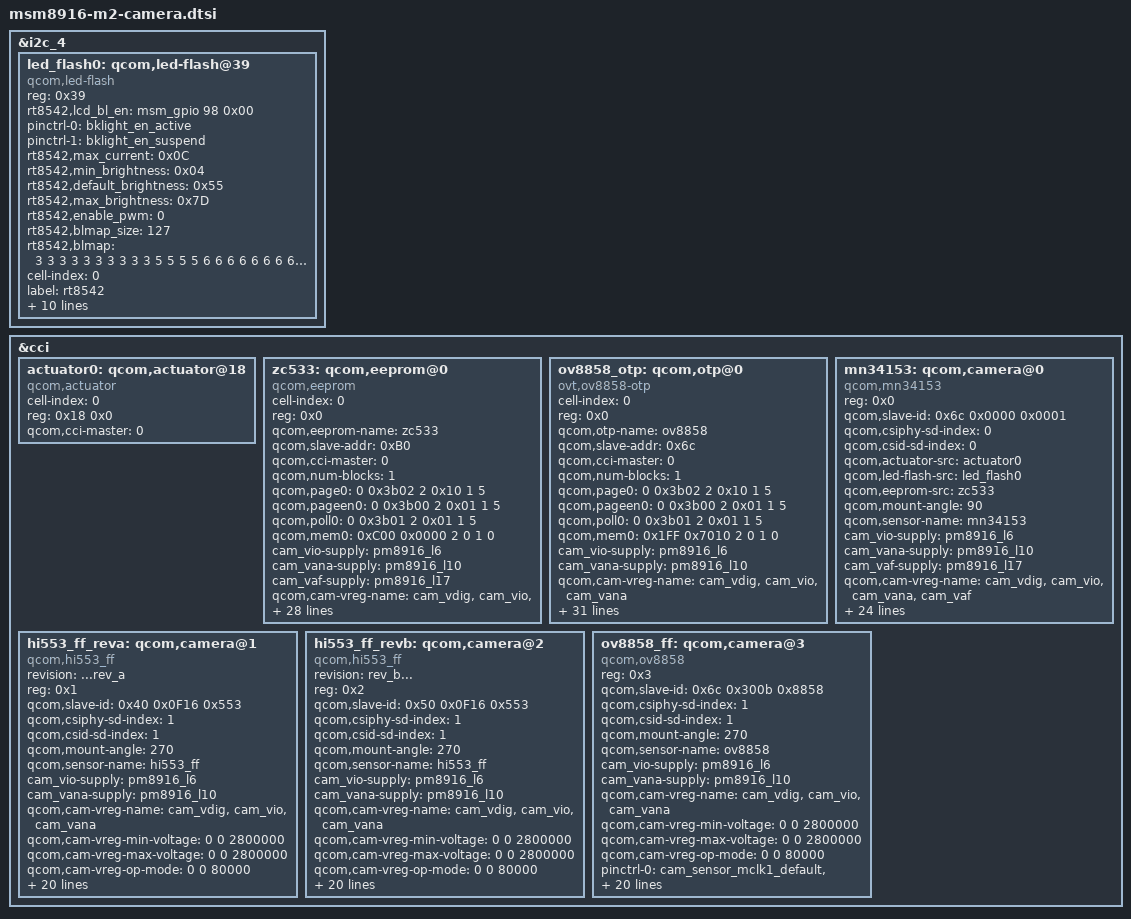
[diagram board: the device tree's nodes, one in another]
/*
 * Copyright (c) 2013, The Linux Foundation. All rights reserved.
 *
 * This program is free software; you can redistribute it and/or modify
 * it under the terms of the GNU General Public License version 2 and
 * only version 2 as published by the Free Software Foundation.
 *
 * This program is distributed in the hope that it will be useful,
 * but WITHOUT ANY WARRANTY; without even the implied warranty of
 * MERCHANTABILITY or FITNESS FOR A PARTICULAR PURPOSE.  See the
 * GNU General Public License for more details.
 */

&i2c_4 {
	led_flash0: qcom,led-flash@39 {
		status = "ok";
		compatible = "qcom,led-flash";
		reg = <0x39>;
		rt8542,lcd_bl_en = <&msm_gpio 98 0x00>;
		pinctrl-names = "default", "sleep";
		pinctrl-0 = <&bklight_en_active>;
		pinctrl-1 = <&bklight_en_suspend>;
		rt8542,max_current = <0x0C>;
		rt8542,min_brightness = <0x04>;
		//rt8542,default_brightness = <0x66>;  //77(0x4D)
		rt8542,default_brightness = <0x55>;	//46(0x2E)
		rt8542,max_brightness = <0x7D>;
		rt8542,enable_pwm = <0>;
		rt8542,blmap_size = <127>;
		rt8542,blmap = <
			3 3 3 3 3 3 3 3 3 3             //9
				5 5 5 5 6 6 6 6 6 6 				//19
				6 6 6 7 7 7 7 7 7 7 				//29
				7 10 10 11 11 11 12 12 12 12 	//39
				14 14 14 14 14 14 15 17 17 17 	//49
				17 19 19 19 21 22 23 23 23 25 	//59
				26 26 29 30 31 32 33 35 35 36	//69
				37 37 38 38 38 39 39 43 43 44 	//79
				44 44 45 45 46 46 46 47 49 50 	//89
				52 52 55 57 59 63 66 68 71 72   //99
				74 74 74 77 78 79 79 81 84 85	//109
				86 88 89 89 89 91 96 99 105 109	//119
				112 115 116 119 122 125 126>;

		cell-index = <0>;
		label                   = "rt8542";
		qcom,flash-name         = "rt8542";
		qcom,slave-id           = <0x39 0x00 0x0011>;
		qcom,flash-type         = <1>;              // LED_FLASH
		qcom,gpio-no-mux        = <0>;
		gpios                   = <&msm_gpio 31 0>; // FLASH_STROBE_TRIG, GPIO 31
		qcom,gpio-flash-en      = <0>;
		qcom,gpio-req-tbl-num   = <0>;
		qcom,gpio-req-tbl-flags = <0>;
		qcom,gpio-req-tbl-label = "FLASH_EN";
		qcom,cci-master = <0>;
	};
};

&cci {
	actuator0: qcom,actuator@18 {
		status = "ok";
		cell-index = <0>;
		reg = <0x18 0x0>;
		compatible = "qcom,actuator";
		qcom,cci-master = <0>;
	};

	zc533: qcom,eeprom@0 {
		status = "ok";
		cell-index = <0>;
		reg = <0x0>;
		qcom,eeprom-name = "zc533";
		compatible = "qcom,eeprom";
		qcom,slave-addr = <0xB0>;
		qcom,cci-master = <0>;
		qcom,num-blocks = <1>;

		qcom,page0 = <0 0x3b02 2 0x10 1 5>;
		qcom,pageen0 = <0 0x3b00 2 0x01 1 5>;
		qcom,poll0 = <0 0x3b01 2 0x01 1 5>;
		qcom,mem0 = <0xC00 0x0000 2 0 1 0>;

		cam_vio-supply = <&pm8916_l6>;
		cam_vana-supply = <&pm8916_l10>;
		cam_vaf-supply = <&pm8916_l17>;

		qcom,cam-vreg-name = "cam_vdig", "cam_vio", "cam_vana", "cam_vaf";
		qcom,cam-vreg-min-voltage = <0 0 2800000 2850000>;
		qcom,cam-vreg-max-voltage = <0 0 2800000 2850000>;
		qcom,cam-vreg-op-mode = <0 0 50000 100000>;

		pinctrl-names = "cam_default", "cam_suspend";
		pinctrl-0 = <&cam_sensor_mclk0_default &cam_sensor_rear_default>;
		pinctrl-1 = <&cam_sensor_mclk0_sleep &cam_sensor_rear_sleep>;

		gpios = <&msm_gpio 26 0>,
			  <&msm_gpio 35 0>,
			  <&msm_gpio 121 0>;

		qcom,gpio-no-mux    = <0>;
		qcom,gpio-reset  = <1>;
		qcom,gpio-vdig      = <2>;
		qcom,gpio-req-tbl-num	= <0 1 2>;
		qcom,gpio-req-tbl-flags	= <0 0 0>;
		qcom,gpio-req-tbl-label	= "CAM0_MCLK",
					"CAM0_RESET",
					"CAM0_DVDD";

		qcom,csi-lane-assign = <0x4320>;
		qcom,csi-lane-mask   = <0x1F>;
		qcom,sensor-position = <0>;
		qcom,sensor-mode     = <0>;

		qcom,cam-power-seq-type = "sensor_vreg", "sensor_gpio", "sensor_vreg", "sensor_vreg";
		qcom,cam-power-seq-val = "cam_vio", "sensor_gpio_vdig", "cam_vana", "cam_vaf";
		qcom,cam-power-seq-cfg-val = <1 1 0 0>;
		qcom,cam-power-seq-delay = <1 1 1 20>;
		qcom,mclk-23880000;

		lge,eeprom-position = <0>;
	};

	ov8858_otp: qcom,otp@0 {
		status = "ok";
		cell-index = <0>;
		reg = <0x0>;
		qcom,otp-name = "ov8858";
		compatible = "ovt,ov8858-otp";
		qcom,slave-addr = <0x6c>;
		qcom,cci-master = <0>;
		qcom,num-blocks = <1>;

		qcom,page0 = <0 0x3b02 2 0x10 1 5>;
		qcom,pageen0 = <0 0x3b00 2 0x01 1 5>;
		qcom,poll0 = <0 0x3b01 2 0x01 1 5>;
		qcom,mem0 = <0x1FF 0x7010 2 0 1 0>;

		cam_vio-supply  = <&pm8916_l6>;
		cam_vana-supply = <&pm8916_l10>;
		qcom,cam-vreg-name = "cam_vdig", "cam_vio", "cam_vana";
		qcom,cam-vreg-min-voltage = <0 0 2800000>;
		qcom,cam-vreg-max-voltage = <0 0 2800000>;
		qcom,cam-vreg-op-mode     = <0 0 80000>;

		pinctrl-names = "cam_default", "cam_suspend";
		pinctrl-0 = <&cam_sensor_mclk1_default &cam_sensor_front_default>;
		pinctrl-1 = <&cam_sensor_mclk1_sleep &cam_sensor_front_sleep>;

		gpios = <&msm_gpio 27  0>,
			<&msm_gpio 28  0>,
			<&msm_gpio 121 0>;

		qcom,gpio-no-mux  = <0>;
		qcom,gpio-reset   = <1>;
		qcom,gpio-vdig    = <2>;

		qcom,gpio-req-tbl-num   = <0 1 2>;
		qcom,gpio-req-tbl-flags = <0 0 0>;
		qcom,gpio-req-tbl-label = "CAM1_MCLK",
		                          "CAM1_RESET",
		                          "CAM1_DVDD";

		qcom,csi-lane-assign    = <0x4320>;
		qcom,csi-lane-mask      = <0x7>;
		qcom,sensor-position    = <1>;
		qcom,sensor-mode        = <1>;

		clocks = <&clock_gcc clk_mclk1_clk_src>,
		         <&clock_gcc clk_gcc_camss_mclk1_clk>;
		clock-names = "cam_src_clk", "cam_clk";

		qcom,cam-power-seq-type = "sensor_vreg", "sensor_gpio", "sensor_vreg", "sensor_gpio", "sensor_clk";
		qcom,cam-power-seq-val = "cam_vio", "sensor_gpio_vdig", "cam_vana", "sensor_gpio_reset", "sensor_cam_mclk";
		qcom,cam-power-seq-cfg-val = <1 1 1 1 23880000>;
		qcom,cam-power-seq-delay = <0 0 0 1 1>;
		qcom,mclk-23880000;

		qcom,otp-position = <1>;
	};

	mn34153: qcom,camera@0 {
		compatible           = "qcom,mn34153";
		reg                  = <0x0>;
		qcom,slave-id        = <0x6c 0x0000 0x0001>;
		qcom,csiphy-sd-index = <0>;
		qcom,csid-sd-index   = <0>;
		qcom,actuator-src    = <&actuator0>;
		qcom,led-flash-src   = <&led_flash0>;
		qcom,eeprom-src      = <&zc533>;
		qcom,mount-angle     = <90>;
		qcom,sensor-name     = "mn34153";

		cam_vio-supply = <&pm8916_l6>;
		cam_vana-supply = <&pm8916_l10>;
		cam_vaf-supply = <&pm8916_l17>;

		qcom,cam-vreg-name = "cam_vdig", "cam_vio", "cam_vana", "cam_vaf";
		qcom,cam-vreg-min-voltage = <0 0 2800000 2850000>;
		qcom,cam-vreg-max-voltage = <0 0 2800000 2850000>;
		qcom,cam-vreg-op-mode = <0 0 50000 100000>;

		pinctrl-names = "cam_default", "cam_suspend";
		pinctrl-0 = <&cam_sensor_mclk0_default &cam_sensor_rear_default>;
		pinctrl-1 = <&cam_sensor_mclk0_sleep &cam_sensor_rear_sleep>;

		gpios = <&msm_gpio 26 0>,
		        <&msm_gpio 35 0>,
			<&msm_gpio 121 0>;

		qcom,gpio-no-mux    = <0>;
		qcom,gpio-reset  = <1>;
		qcom,gpio-vdig      = <2>;
		qcom,gpio-req-tbl-num	= <0 1 2>;
		qcom,gpio-req-tbl-flags	= <0 0 0>;
		qcom,gpio-req-tbl-label	= "CAM0_MCLK",
					"CAM0_RESET",
					"CAM0_DVDD";

		qcom,csi-lane-assign = <0x4320>;
		qcom,csi-lane-mask   = <0x1F>;
		qcom,sensor-position = <0>;
		qcom,sensor-mode     = <0>;
		qcom,cci-master      = <0>;

		status = "ok";
		clocks = <&clock_gcc clk_mclk0_clk_src>,
				 <&clock_gcc clk_gcc_camss_mclk0_clk>;
		clock-names = "cam_src_clk", "cam_clk";
		qcom,mclk-23880000;

		lge,vcm-pwdn = "zc533";
	};

	hi553_ff_reva: qcom,camera@1 {
		status = "ok";
		compatible           = "qcom,hi553_ff";
		revision = "...rev_a";
		reg                  = <0x1>;
		qcom,slave-id        = <0x40 0x0F16 0x553>;
		qcom,csiphy-sd-index = <1>;
		qcom,csid-sd-index   = <1>;
		qcom,mount-angle     = <270>;
		qcom,sensor-name     = "hi553_ff";

		cam_vio-supply  = <&pm8916_l6>;
		cam_vana-supply = <&pm8916_l10>;
		qcom,cam-vreg-name = "cam_vdig", "cam_vio", "cam_vana";
		qcom,cam-vreg-min-voltage = <0 0 2800000>;
		qcom,cam-vreg-max-voltage = <0 0 2800000>;
		qcom,cam-vreg-op-mode     = <0 0 80000>;

		pinctrl-names = "cam_default", "cam_suspend";
		pinctrl-0 = <&cam_sensor_mclk1_default &cam_sensor_front_default>;
		pinctrl-1 = <&cam_sensor_mclk1_sleep &cam_sensor_front_sleep>;

		gpios = <&msm_gpio 27  0>,
			<&msm_gpio 28  0>,
			<&msm_gpio 121 0>;

		qcom,gpio-no-mux  = <0>;
		qcom,gpio-reset   = <1>;
		qcom,gpio-vdig    = <2>;

		qcom,gpio-req-tbl-num   = <0 1 2>;
		qcom,gpio-req-tbl-flags = <0 0 0>;
		qcom,gpio-req-tbl-label = "CAM1_MCLK",
		                          "CAM1_RESET",
		                          "CAM1_DVDD";

		qcom,csi-lane-assign    = <0x4320>;
		qcom,csi-lane-mask      = <0x7>;
		qcom,sensor-position    = <1>;
		qcom,sensor-mode        = <1>;
		qcom,cci-master         = <0>;

		clocks = <&clock_gcc clk_mclk1_clk_src>,
		         <&clock_gcc clk_gcc_camss_mclk1_clk>;
		clock-names = "cam_src_clk", "cam_clk";

		qcom,mclk-23880000;
	};

	hi553_ff_revb: qcom,camera@2 {
		status = "ok";
		compatible           = "qcom,hi553_ff";
		revision = "rev_b...";
		reg                  = <0x2>;
		qcom,slave-id        = <0x50 0x0F16 0x553>;
		qcom,csiphy-sd-index = <1>;
		qcom,csid-sd-index   = <1>;
		qcom,mount-angle     = <270>;
		qcom,sensor-name     = "hi553_ff";

		cam_vio-supply  = <&pm8916_l6>;
		cam_vana-supply = <&pm8916_l10>;
		qcom,cam-vreg-name = "cam_vdig", "cam_vio", "cam_vana";
		qcom,cam-vreg-min-voltage = <0 0 2800000>;
		qcom,cam-vreg-max-voltage = <0 0 2800000>;
		qcom,cam-vreg-op-mode     = <0 0 80000>;

		pinctrl-names = "cam_default", "cam_suspend";
		pinctrl-0 = <&cam_sensor_mclk1_default &cam_sensor_front_default>;
		pinctrl-1 = <&cam_sensor_mclk1_sleep &cam_sensor_front_sleep>;

		gpios = <&msm_gpio 27  0>,
			<&msm_gpio 28  0>,
			<&msm_gpio 121 0>;

		qcom,gpio-no-mux  = <0>;
		qcom,gpio-reset   = <1>;
		qcom,gpio-vdig    = <2>;

		qcom,gpio-req-tbl-num   = <0 1 2>;
		qcom,gpio-req-tbl-flags = <0 0 0>;
		qcom,gpio-req-tbl-label = "CAM1_MCLK",
		                          "CAM1_RESET",
		                          "CAM1_DVDD";

		qcom,csi-lane-assign    = <0x4320>;
		qcom,csi-lane-mask      = <0x7>;
		qcom,sensor-position    = <1>;
		qcom,sensor-mode        = <1>;
		qcom,cci-master         = <0>;

		clocks = <&clock_gcc clk_mclk1_clk_src>,
		         <&clock_gcc clk_gcc_camss_mclk1_clk>;
		clock-names = "cam_src_clk", "cam_clk";

		qcom,mclk-23880000;
	};

	ov8858_ff: qcom,camera@3 {
		status = "ok";
		compatible           = "qcom,ov8858";
		reg                  = <0x3>;
		qcom,slave-id        = <0x6c 0x300b 0x8858>;
		qcom,csiphy-sd-index = <1>;
		qcom,csid-sd-index   = <1>;
		qcom,mount-angle     = <270>;
		qcom,sensor-name     = "ov8858";

		cam_vio-supply  = <&pm8916_l6>;
		cam_vana-supply = <&pm8916_l10>;
		qcom,cam-vreg-name = "cam_vdig", "cam_vio", "cam_vana";
		qcom,cam-vreg-min-voltage = <0 0 2800000>;
		qcom,cam-vreg-max-voltage = <0 0 2800000>;
		qcom,cam-vreg-op-mode     = <0 0 80000>;

		pinctrl-names = "cam_default", "cam_suspend";
		pinctrl-0 = <&cam_sensor_mclk1_default &cam_sensor_front_default>;
		pinctrl-1 = <&cam_sensor_mclk1_sleep &cam_sensor_front_sleep>;

		gpios = <&msm_gpio 27  0>,
			<&msm_gpio 28  0>,
			<&msm_gpio 121 0>;

		qcom,gpio-no-mux  = <0>;
		qcom,gpio-reset   = <1>;
		qcom,gpio-vdig    = <2>;

		qcom,gpio-req-tbl-num   = <0 1 2>;
		qcom,gpio-req-tbl-flags = <0 0 0>;
		qcom,gpio-req-tbl-label = "CAM1_MCLK",
		                          "CAM1_RESET",
		                          "CAM1_DVDD";

		qcom,csi-lane-assign    = <0x4320>;
		qcom,csi-lane-mask      = <0x7>;
		qcom,sensor-position    = <1>;
		qcom,sensor-mode        = <1>;
		qcom,cci-master         = <0>;

		clocks = <&clock_gcc clk_mclk1_clk_src>,
		         <&clock_gcc clk_gcc_camss_mclk1_clk>;
		clock-names = "cam_src_clk", "cam_clk";

		qcom,mclk-23880000;
		qcom,otp-src = <&ov8858_otp>;
	};
};
